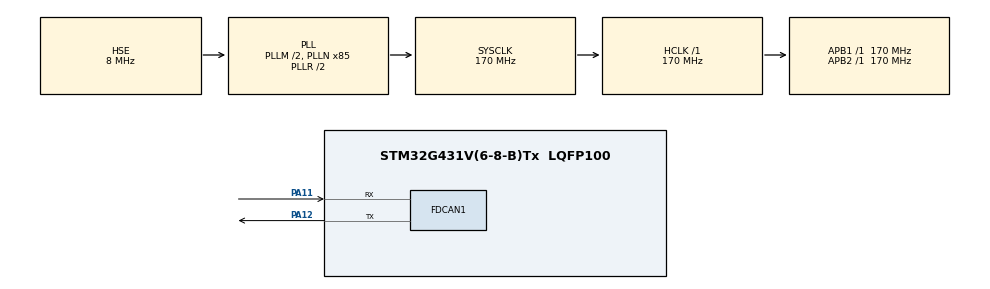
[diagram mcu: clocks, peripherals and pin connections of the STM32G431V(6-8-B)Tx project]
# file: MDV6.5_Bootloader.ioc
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FDCAN1.AutoRetransmission=ENABLE
FDCAN1.CalculateBaudRateNominal=999999
FDCAN1.CalculateTimeBitNominal=1000
FDCAN1.CalculateTimeQuantumNominal=58.82352941176471
FDCAN1.NominalPrescaler=10
FDCAN1.NominalSyncJumpWidth=4
FDCAN1.NominalTimeSeg1=12
FDCAN1.NominalTimeSeg2=4
Mcu.Family=STM32G4
Mcu.Name=STM32G431V(6-8-B)Tx
Mcu.Package=LQFP100
NVIC.PriorityGroup=NVIC_PRIORITYGROUP_4
PA11.Mode=FDCAN_Activate
PA11.Signal=FDCAN1_RX
PA12.Mode=FDCAN_Activate
PA12.Signal=FDCAN1_TX
PF0-OSC_IN.Mode=HSE-External-Oscillator
PF0-OSC_IN.Signal=RCC_OSC_IN
PF1-OSC_OUT.Mode=HSE-External-Oscillator
PF1-OSC_OUT.Signal=RCC_OSC_OUT
ProjectManager.HeapSize=0x200
ProjectManager.StackSize=0x400
ProjectManager.TargetToolchain=STM32CubeIDE
RCC.ADC12Freq_Value=170000000
RCC.AHBFreq_Value=170000000
RCC.APB1Freq_Value=170000000
RCC.APB1TimFreq_Value=170000000
RCC.APB2Freq_Value=170000000
RCC.APB2TimFreq_Value=170000000
RCC.CortexFreq_Value=170000000
RCC.EXTERNAL_CLOCK_VALUE=12288000
RCC.HCLKFreq_Value=170000000
RCC.HSE_VALUE=8000000
RCC.HSI48_VALUE=48000000
RCC.HSI_VALUE=16000000
RCC.LSE_VALUE=32768
RCC.PLLM=RCC_PLLM_DIV2
RCC.PLLN=85
RCC.PLLSourceVirtual=RCC_PLLSOURCE_HSE
RCC.SYSCLKFreq_VALUE=170000000
RCC.SYSCLKSource=RCC_SYSCLKSOURCE_PLLCLK
RCC.USBFreq_Value=170000000
RCC.VCOOutputFreq_Value=340000000
VP_CRC_VS_CRC.Mode=CRC_Activate
VP_SYS_VS_DBSignals.Mode=DisableDeadBatterySignals
board=custom

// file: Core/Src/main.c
/* USER CODE BEGIN Header */
/**
  ******************************************************************************
  * @file           : main.c
  * @brief          : Main program body
  ******************************************************************************
  * @attention
  *
  * Copyright (c) 2026 STMicroelectronics.
  * All rights reserved.
  *
  * This software is licensed under terms that can be found in the LICENSE file
  * in the root directory of this software component.
  * If no LICENSE file comes with this software, it is provided AS-IS.
  *
  ******************************************************************************
  */
/* USER CODE END Header */
#include "main.h"

/* USER CODE BEGIN Includes */
#include <string.h>
/* USER CODE END Includes */

/* USER CODE BEGIN PTD */
typedef void (*app_entry_t)(void);
/* USER CODE END PTD */

/* USER CODE BEGIN PD */
#define APP_BASE_ADDRESS	0x08008000
#define MAX_APP_SIZE		(96 * 1024)
//BOOTLODAER MESSAGE IDS
#define CAN_ID_BOOT			0x700
#define CAN_ID_START		0x701
#define CAN_ID_DATA			0x702
#define CAN_ID_END			0x703

// RAM flag for clean reset-then-jump (survives NVIC_SystemReset)
#define BOOT_TO_APP_FLAG	(*((volatile uint32_t*)0x20007F00))
#define BOOT_TO_APP_MAGIC	0xB007A990
/* USER CODE END PD */

CRC_HandleTypeDef hcrc;

FDCAN_HandleTypeDef hfdcan1;

/* USER CODE BEGIN PV */
uint32_t writeAddress;
uint32_t totalSize;
uint32_t bytesReceived;
uint32_t currentCRC;
uint8_t transferActive = 0;
/* USER CODE END PV */

void SystemClock_Config(void);
static void MX_GPIO_Init(void);
static void MX_FDCAN1_Init(void);
static void MX_CRC_Init(void);
/* USER CODE BEGIN PFP */
void JumpToApplication(void);
void TransferFailed(void);
uint8_t AppIsValid(void);
HAL_StatusTypeDef FlashErase(void);
HAL_StatusTypeDef FlashWrite(uint32_t address, uint8_t *data, uint32_t length);
/* USER CODE END PFP */

int main(void)
{
	/* USER CODE BEGIN 1 */
	// Check RAM flag: if set, we came from NVIC_SystemReset after a flash
	// All peripherals are in clean reset state — jump straight to app
	if (BOOT_TO_APP_FLAG == BOOT_TO_APP_MAGIC){
		BOOT_TO_APP_FLAG = 0;
		SCB->VTOR = APP_BASE_ADDRESS;
		__set_MSP(*((volatile uint32_t*)APP_BASE_ADDRESS));
		((void(*)(void))(*((volatile uint32_t*)(APP_BASE_ADDRESS + 4))))();
	}
	/* USER CODE END 1 */

	/* MCU Configuration--------------------------------------------------------*/

	/* Reset of all peripherals, Initializes the Flash interface and the Systick. */
	HAL_Init();

	/* Configure the system clock */
	SystemClock_Config();

	/* Initialize all configured peripherals */
	MX_GPIO_Init();
	MX_FDCAN1_Init();
	MX_CRC_Init();
	/* USER CODE BEGIN 2 */

	// LED on PC13
	GPIO_InitTypeDef GPIO_InitStruct = {0};
	__HAL_RCC_GPIOC_CLK_ENABLE();
	GPIO_InitStruct.Pin = GPIO_PIN_13;
	GPIO_InitStruct.Mode = GPIO_MODE_OUTPUT_PP;
	GPIO_InitStruct.Pull = GPIO_NOPULL;
	GPIO_InitStruct.Speed = GPIO_SPEED_FREQ_LOW;
	HAL_GPIO_Init(GPIOC, &GPIO_InitStruct);

	// Blink LED 3 times to indicate bootloader mode
	for (int i = 0; i < 6; i++){
		HAL_GPIO_TogglePin(GPIOC, GPIO_PIN_13);
		HAL_Delay(500);
	}
	HAL_GPIO_WritePin(GPIOC, GPIO_PIN_13, GPIO_PIN_RESET);

	// Single CAN filter for bootloader IDs 0x700-0x703
	// Mask 0x7FC = ignore bottom 2 bits, match 0x700 base
	FDCAN_FilterTypeDef sFilterConfig;
	sFilterConfig.IdType = FDCAN_STANDARD_ID;
	sFilterConfig.FilterIndex = 0;
	sFilterConfig.FilterType = FDCAN_FILTER_MASK;
	sFilterConfig.FilterConfig = FDCAN_FILTER_TO_RXFIFO0;
	sFilterConfig.FilterID1 = CAN_ID_BOOT;	// 0x700
	sFilterConfig.FilterID2 = 0x7FC;		// mask: accept 0x700-0x703
	HAL_FDCAN_ConfigFilter(&hfdcan1, &sFilterConfig);

	HAL_FDCAN_ConfigGlobalFilter(&hfdcan1, FDCAN_REJECT, FDCAN_REJECT,
			FDCAN_FILTER_REMOTE, FDCAN_FILTER_REMOTE);

	if (HAL_FDCAN_Start(&hfdcan1) != HAL_OK) {
		Error_Handler();
	}

	// Quick blink to indicate CAN is ready
	HAL_GPIO_TogglePin(GPIOC, GPIO_PIN_13);
	HAL_Delay(100);
	HAL_GPIO_TogglePin(GPIOC, GPIO_PIN_13);

	/* USER CODE END 2 */

	/* Infinite loop */
	while (1)
	{
		//see if "mailbox" is populated
		if (HAL_FDCAN_GetRxFifoFillLevel(&hfdcan1, FDCAN_RX_FIFO0) > 0)
		{
			//RxHeader Instance
			FDCAN_RxHeaderTypeDef RxHeader;
			uint8_t RxData[8];

			//if no error in retrieving message
			if (HAL_FDCAN_GetRxMessage(&hfdcan1, FDCAN_RX_FIFO0, &RxHeader, RxData) == HAL_OK)
			{
				//BOOT, START FLASHING, DATA, OR END FLASHING.
				switch (RxHeader.Identifier)
				{

					case CAN_ID_BOOT:
						HAL_GPIO_WritePin(GPIOC, GPIO_PIN_13, GPIO_PIN_SET);
						if (AppIsValid()) JumpToApplication();
						break;

					case CAN_ID_START:
						HAL_GPIO_WritePin(GPIOC, GPIO_PIN_13, GPIO_PIN_SET);
						memcpy(&totalSize, RxData, 4);
						if (totalSize > MAX_APP_SIZE || totalSize % 8 != 0) { TransferFailed(); break; }
						HAL_FLASH_Unlock();
						if (FlashErase() != HAL_OK) { HAL_FLASH_Lock(); TransferFailed(); break; }
						HAL_GPIO_WritePin(GPIOC, GPIO_PIN_13, GPIO_PIN_RESET);
						currentCRC = 0;
						__HAL_CRC_DR_RESET(&hcrc);
						writeAddress = APP_BASE_ADDRESS;
						bytesReceived = 0;
						transferActive = 1;
						break;

					case CAN_ID_DATA:
						if (!transferActive) break;
						if (bytesReceived + 8 > totalSize) { HAL_FLASH_Lock(); TransferFailed(); break; }
						if (FlashWrite(writeAddress, RxData, 8) != HAL_OK) { HAL_FLASH_Lock(); TransferFailed(); break; }
						currentCRC = HAL_CRC_Accumulate(&hcrc, (uint32_t*)RxData, 8);
						writeAddress += 8;
						bytesReceived += 8;
						break;

					case CAN_ID_END:
					{
						uint32_t receivedCRC;
						memcpy(&receivedCRC, RxData, 4);
						HAL_FLASH_Lock();
						if (!transferActive) break;
						if (bytesReceived != totalSize) { TransferFailed(); break; }
						if (currentCRC == receivedCRC)
							JumpToApplication();
						else
							TransferFailed();
						break;
					}
				}
			}
		}
	}
}

void SystemClock_Config(void)
{
	RCC_OscInitTypeDef RCC_OscInitStruct = {0};
	RCC_ClkInitTypeDef RCC_ClkInitStruct = {0};

	HAL_PWREx_ControlVoltageScaling(PWR_REGULATOR_VOLTAGE_SCALE1_BOOST);

	RCC_OscInitStruct.OscillatorType = RCC_OSCILLATORTYPE_HSE;
	RCC_OscInitStruct.HSEState = RCC_HSE_ON;
	RCC_OscInitStruct.PLL.PLLState = RCC_PLL_ON;
	RCC_OscInitStruct.PLL.PLLSource = RCC_PLLSOURCE_HSE;
	RCC_OscInitStruct.PLL.PLLM = RCC_PLLM_DIV2;
	RCC_OscInitStruct.PLL.PLLN = 85;
	RCC_OscInitStruct.PLL.PLLP = RCC_PLLP_DIV2;
	RCC_OscInitStruct.PLL.PLLQ = RCC_PLLQ_DIV2;
	RCC_OscInitStruct.PLL.PLLR = RCC_PLLR_DIV2;
	if (HAL_RCC_OscConfig(&RCC_OscInitStruct) != HAL_OK)
	{
		Error_Handler();
	}

	RCC_ClkInitStruct.ClockType = RCC_CLOCKTYPE_HCLK|RCC_CLOCKTYPE_SYSCLK
								|RCC_CLOCKTYPE_PCLK1|RCC_CLOCKTYPE_PCLK2;
	RCC_ClkInitStruct.SYSCLKSource = RCC_SYSCLKSOURCE_PLLCLK;
	RCC_ClkInitStruct.AHBCLKDivider = RCC_SYSCLK_DIV1;
	RCC_ClkInitStruct.APB1CLKDivider = RCC_HCLK_DIV1;
	RCC_ClkInitStruct.APB2CLKDivider = RCC_HCLK_DIV1;

	if (HAL_RCC_ClockConfig(&RCC_ClkInitStruct, FLASH_LATENCY_4) != HAL_OK)
	{
		Error_Handler();
	}
}

static void MX_CRC_Init(void)
{

	hcrc.Instance = CRC;
	hcrc.Init.DefaultPolynomialUse = DEFAULT_POLYNOMIAL_ENABLE;
	hcrc.Init.DefaultInitValueUse = DEFAULT_INIT_VALUE_ENABLE;
	hcrc.Init.InputDataInversionMode = CRC_INPUTDATA_INVERSION_NONE;
	hcrc.Init.OutputDataInversionMode = CRC_OUTPUTDATA_INVERSION_DISABLE;
	hcrc.InputDataFormat = CRC_INPUTDATA_FORMAT_BYTES;
	if (HAL_CRC_Init(&hcrc) != HAL_OK)
	{
		Error_Handler();
	}
}

static void MX_FDCAN1_Init(void)
{

	hfdcan1.Instance = FDCAN1;
	hfdcan1.Init.ClockDivider = FDCAN_CLOCK_DIV1;
	hfdcan1.Init.FrameFormat = FDCAN_FRAME_CLASSIC;
	hfdcan1.Init.Mode = FDCAN_MODE_NORMAL;
	hfdcan1.Init.AutoRetransmission = ENABLE;
	hfdcan1.Init.TransmitPause = DISABLE;
	hfdcan1.Init.ProtocolException = DISABLE;
	hfdcan1.Init.NominalPrescaler = 10;
	hfdcan1.Init.NominalSyncJumpWidth = 4;
	hfdcan1.Init.NominalTimeSeg1 = 12;
	hfdcan1.Init.NominalTimeSeg2 = 4;
	hfdcan1.Init.DataPrescaler = 1;
	hfdcan1.Init.DataSyncJumpWidth = 1;
	hfdcan1.Init.DataTimeSeg1 = 1;
	hfdcan1.Init.DataTimeSeg2 = 1;
	hfdcan1.Init.StdFiltersNbr = 1;
	hfdcan1.Init.ExtFiltersNbr = 0;
	hfdcan1.Init.TxFifoQueueMode = FDCAN_TX_FIFO_OPERATION;
	if (HAL_FDCAN_Init(&hfdcan1) != HAL_OK)
	{
		Error_Handler();
	}
}

static void MX_GPIO_Init(void)
{

	/* GPIO Ports Clock Enable */
	__HAL_RCC_GPIOF_CLK_ENABLE();
	__HAL_RCC_GPIOA_CLK_ENABLE();

}

/* USER CODE BEGIN 4 */
uint8_t AppIsValid(void)
{
	uint32_t sp = *((volatile uint32_t*)APP_BASE_ADDRESS);
	return (sp >= 0x20000000 && sp <= 0x20008000);
}

void TransferFailed(void)
{
	transferActive = 0;
	for (int i = 0; i < 10; i++)
	{
		HAL_GPIO_TogglePin(GPIOC, GPIO_PIN_13);
		HAL_Delay(100);
	}
	HAL_GPIO_WritePin(GPIOC, GPIO_PIN_13, GPIO_PIN_RESET);
}

void JumpToApplication(void)
{
	// Set RAM flag and do a full hardware reset
	// On reboot, main() sees the flag and jumps to app with clean peripheral state
	BOOT_TO_APP_FLAG = BOOT_TO_APP_MAGIC;
	NVIC_SystemReset();
}

HAL_StatusTypeDef FlashErase(void)
{
	FLASH_EraseInitTypeDef eraseConfig;
	eraseConfig.TypeErase = FLASH_TYPEERASE_PAGES;
	eraseConfig.Banks = FLASH_BANK_1;
	eraseConfig.Page = 16;		// page 16 = 0x08008000
	eraseConfig.NbPages = 48;	// pages 16-63 = 96 KB
	uint32_t pageError;
	return HAL_FLASHEx_Erase(&eraseConfig, &pageError);
}

HAL_StatusTypeDef FlashWrite(uint32_t address, uint8_t *data, uint32_t length)
{
	HAL_StatusTypeDef status = HAL_OK;
	for (uint32_t i = 0; i < length; i += 8)
	{
		uint64_t chunk;
		memcpy(&chunk, data + i, 8);
		status = HAL_FLASH_Program(FLASH_TYPEPROGRAM_DOUBLEWORD, address + i, chunk);
		if (status != HAL_OK) break;
	}
	return status;
}
/* USER CODE END 4 */

void Error_Handler(void)
{
	__disable_irq();
	while (1)
	{
	}
}
